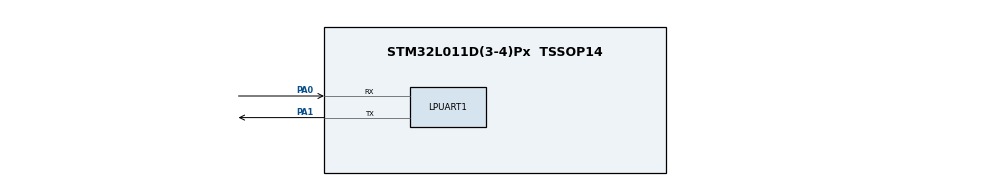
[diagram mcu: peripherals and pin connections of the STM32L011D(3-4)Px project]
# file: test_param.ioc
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Mcu.Family=STM32L0
Mcu.Name=STM32L011D(3-4)Px
Mcu.Package=TSSOP14
NVIC.LPUART1_IRQn=true\:0\:0\:false\:false\:true\:true\:true\:true
PA0-CK_IN.Mode=Asynchronous
PA0-CK_IN.Signal=LPUART1_RX
PA1.Mode=Asynchronous
PA1.Signal=LPUART1_TX
PA13.Mode=Serial_Wire
PA13.Signal=SYS_SWDIO
PA14.Mode=Serial_Wire
PA14.Signal=SYS_SWCLK
ProjectManager.HeapSize=0x200
ProjectManager.StackSize=0x400
ProjectManager.TargetToolchain=STM32CubeIDE
RCC.AHBFreq_Value=32000000
RCC.APB1Freq_Value=32000000
RCC.APB1TimFreq_Value=32000000
RCC.APB2Freq_Value=32000000
RCC.APB2TimFreq_Value=32000000
RCC.HCLKFreq_Value=32000000
RCC.HSE_VALUE=8000000
RCC.HSI16_VALUE=16000000
RCC.HSI_VALUE=16000000
RCC.LSE_VALUE=32768
RCC.MSI_VALUE=2097000
RCC.PLLMUL=RCC_PLLMUL_4
RCC.SYSCLKFreq_VALUE=32000000
RCC.SYSCLKSource=RCC_SYSCLKSOURCE_PLLCLK
RCC.VCOOutputFreq_Value=64000000
board=custom

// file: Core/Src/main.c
/* USER CODE BEGIN Header */
/**
  ******************************************************************************
  * @file           : main.c
  * @brief          : Main program body
  ******************************************************************************
  * @attention
  *
  * Copyright (c) 2024 STMicroelectronics.
  * All rights reserved.
  *
  * This software is licensed under terms that can be found in the LICENSE file
  * in the root directory of this software component.
  * If no LICENSE file comes with this software, it is provided AS-IS.
  *
  ******************************************************************************
  */
/* USER CODE END Header */
#include "main.h"

/* USER CODE BEGIN Includes */
#include "param_main.h"
/* USER CODE END Includes */

UART_HandleTypeDef hlpuart1;

void SystemClock_Config(void);
static void MX_GPIO_Init(void);
static void MX_LPUART1_UART_Init(void);

/* USER CODE BEGIN 0 */
extern void Param_RxCallback(uint8_t byte);

uint8_t buff1[100];
uint8_t Fill(uint8_t *data, uint8_t len, uint8_t type)
{
	buff1[0] = len;
	buff1[1] = type;
	buff1[2] = 0;
	buff1[3] = 0;
	for (int i=0; i<len; i++)
		buff1[4+i] = data[i];
	uint8_t cs = 0;
	for (int i=0; i<len+4; i++)
		cs ^= buff1[i];
	buff1[2] = cs;
	return 4+ len;
}

/* USER CODE END 0 */

int main(void)
{

  /* MCU Configuration--------------------------------------------------------*/

  /* Reset of all peripherals, Initializes the Flash interface and the Systick. */
  HAL_Init();

  /* Configure the system clock */
  SystemClock_Config();

  /* Initialize all configured peripherals */
  MX_GPIO_Init();
  MX_LPUART1_UART_Init();
  /* USER CODE BEGIN 2 */
  Param_Init(NULL, 0, 0);
  // Вызываем в прерывании при получении байта
  //Param_RecieveByte_Callback(1);
  volatile uint8_t a = 00;
  volatile uint32_t param_wr = 0;
  volatile uint8_t param_n = 0;
  volatile uint16_t dump = 0;
  /* USER CODE END 2 */

  /* Infinite loop */
  /* USER CODE BEGIN WHILE */
  while (1)
  {
	  uint8_t len = 0;

	  switch (a)
	  {
	  case 0xFF:
		  break;
	  case 0: // info
		  len = Fill(NULL, 0, 0x80+a);
		  break;
	  case 1: // get stat
		  len = Fill(&param_n, 1,  0x80+a);
		  break;
	  case 2: // reset stat
		  len = Fill(NULL, 0,  0x80+a);
		  break;
	  case 3: // get param
		  len = Fill(&param_n, 1,  0x80+a);
		  break;
	  case 4: // write param
	 	  len = Fill(&param_wr, 5,  0x80+a);
		  break;
	  case 6: // dump
		  len = Fill(&dump, 2,  0x80+a);
		  break;
	  case 7: // reset
		  len = Fill(NULL, 0,  0x80+a);
		  break;
	  case 8: // fw
		  len = Fill(NULL, 0,  0x80+a);
		  break;
	  }

	  for (int i=0; i<len; i++)
		Param_RxCallback(buff1[i]);

	  a = 0xFF;
    /* USER CODE END WHILE */

  }
}

void SystemClock_Config(void)
{
  LL_FLASH_SetLatency(LL_FLASH_LATENCY_1);
  while(LL_FLASH_GetLatency()!= LL_FLASH_LATENCY_1)
  {
  }
  LL_PWR_SetRegulVoltageScaling(LL_PWR_REGU_VOLTAGE_SCALE1);
  while (LL_PWR_IsActiveFlag_VOS() != 0)
  {
  }
  LL_RCC_HSI_Enable();

   /* Wait till HSI is ready */
  while(LL_RCC_HSI_IsReady() != 1)
  {

  }
  LL_RCC_HSI_SetCalibTrimming(16);
  LL_RCC_PLL_ConfigDomain_SYS(LL_RCC_PLLSOURCE_HSI, LL_RCC_PLL_MUL_4, LL_RCC_PLL_DIV_2);
  LL_RCC_PLL_Enable();

   /* Wait till PLL is ready */
  while(LL_RCC_PLL_IsReady() != 1)
  {

  }
  LL_RCC_SetAHBPrescaler(LL_RCC_SYSCLK_DIV_1);
  LL_RCC_SetAPB1Prescaler(LL_RCC_APB1_DIV_1);
  LL_RCC_SetAPB2Prescaler(LL_RCC_APB2_DIV_1);
  LL_RCC_SetSysClkSource(LL_RCC_SYS_CLKSOURCE_PLL);

   /* Wait till System clock is ready */
  while(LL_RCC_GetSysClkSource() != LL_RCC_SYS_CLKSOURCE_STATUS_PLL)
  {

  }
  LL_SetSystemCoreClock(32000000);

   /* Update the time base */
  if (HAL_InitTick (TICK_INT_PRIORITY) != HAL_OK)
  {
    Error_Handler();
  }
  LL_RCC_SetLPUARTClockSource(LL_RCC_LPUART1_CLKSOURCE_PCLK1);
}

static void MX_LPUART1_UART_Init(void)
{

  hlpuart1.Instance = LPUART1;
  hlpuart1.Init.BaudRate = 209700;
  hlpuart1.Init.WordLength = UART_WORDLENGTH_7B;
  hlpuart1.Init.StopBits = UART_STOPBITS_1;
  hlpuart1.Init.Parity = UART_PARITY_NONE;
  hlpuart1.Init.Mode = UART_MODE_TX_RX;
  hlpuart1.Init.HwFlowCtl = UART_HWCONTROL_NONE;
  hlpuart1.Init.OneBitSampling = UART_ONE_BIT_SAMPLE_DISABLE;
  hlpuart1.AdvancedInit.AdvFeatureInit = UART_ADVFEATURE_NO_INIT;
  if (HAL_UART_Init(&hlpuart1) != HAL_OK)
  {
    Error_Handler();
  }

}

static void MX_GPIO_Init(void)
{

  /* GPIO Ports Clock Enable */
  LL_IOP_GRP1_EnableClock(LL_IOP_GRP1_PERIPH_GPIOA);

}

void Error_Handler(void)
{
  __disable_irq();
  while (1)
  {
  }
}
